# dsPIC33FJ64GS606 register map
Vendor: Microchip; Series: dsPIC33FJ64GS; File version: 1.4.228
Registers are 16-bit, read-write, no defined reset value unless marked. A register's access mark holds for its fields unless they carry their own. Offsets are from the block's base; [hi:lo] are bit positions; {n}, {i} and the like mark numbered series.

## PWM6 — PWM6 peripheral registers
Base 0x000004C0
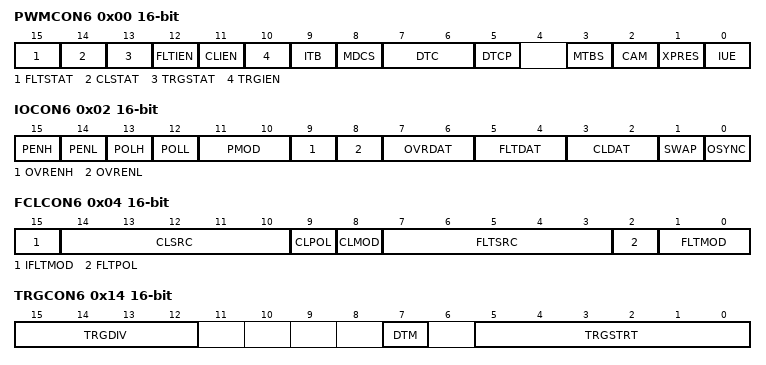
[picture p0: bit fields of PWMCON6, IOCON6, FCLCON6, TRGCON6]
0x00 PWMCON6
  [15] FLTSTAT — PWMCON6 field FLTSTAT
  [14] CLSTAT — PWMCON6 field CLSTAT
  [13] TRGSTAT — PWMCON6 field TRGSTAT
  [12] FLTIEN — PWMCON6 field FLTIEN
  [11] CLIEN — PWMCON6 field CLIEN
  [10] TRGIEN — PWMCON6 field TRGIEN
  [9] ITB — PWMCON6 field ITB
  [8] MDCS — PWMCON6 field MDCS
  [7:6] DTC — PWMCON6 field DTC
  [5] DTCP — PWMCON6 field DTCP
  [3] MTBS — PWMCON6 field MTBS
  [2] CAM — PWMCON6 field CAM
  [1] XPRES — PWMCON6 field XPRES
  [0] IUE — PWMCON6 field IUE
0x02 IOCON6
  [15] PENH — IOCON6 field PENH
  [14] PENL — IOCON6 field PENL
  [13] POLH — IOCON6 field POLH
  [12] POLL — IOCON6 field POLL
  [11:10] PMOD — IOCON6 field PMOD
  [9] OVRENH — IOCON6 field OVRENH
  [8] OVRENL — IOCON6 field OVRENL
  [7:6] OVRDAT — IOCON6 field OVRDAT
  [5:4] FLTDAT — IOCON6 field FLTDAT
  [3:2] CLDAT — IOCON6 field CLDAT
  [1] SWAP — IOCON6 field SWAP
  [0] OSYNC — IOCON6 field OSYNC
0x04 FCLCON6
  [15] IFLTMOD — FCLCON6 field IFLTMOD
  [14:10] CLSRC — FCLCON6 field CLSRC
  [9] CLPOL — FCLCON6 field CLPOL
  [8] CLMOD — FCLCON6 field CLMOD
  [7:3] FLTSRC — FCLCON6 field FLTSRC
  [2] FLTPOL — FCLCON6 field FLTPOL
  [1:0] FLTMOD — FCLCON6 field FLTMOD
0x06 PDC6
  [15:0] PDC6 — PDC6 register value
0x08 PHASE6
  [15:0] PHASE6 — PHASE6 register value
0x0A DTR6
  [13:0] DTR — DTR6 dead-time value
0x0C ALTDTR6
  [13:0] ALTDTR — ALTDTR6 dead-time value
0x0E SDC6
  [15:0] SDC6 — SDC6 register value
0x10 SPHASE6
  [15:0] SPHASE6 — SPHASE6 register value
0x12 TRIG6
  [15:3] TRGCMP — TRIG6 field TRGCMP
0x14 TRGCON6
  [15:12] TRGDIV — TRGCON6 field TRGDIV
  [7] DTM — TRGCON6 field DTM
  [5:0] TRGSTRT — TRGCON6 field TRGSTRT
0x16 STRIG6
  [15:3] STRGCMP — STRIG6 field STRGCMP
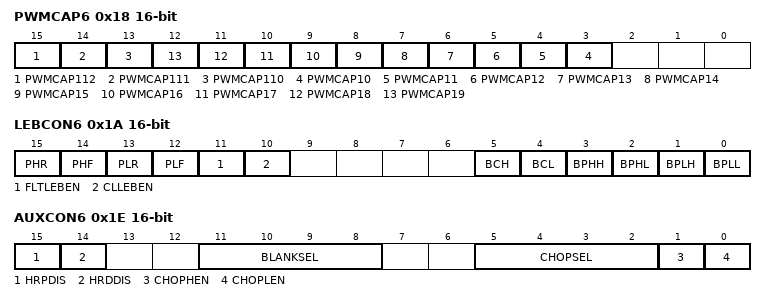
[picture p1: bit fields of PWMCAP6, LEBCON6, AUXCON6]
0x18 PWMCAP6
  [15] PWMCAP112 — PWMCAP6 field PWMCAP112
  [14] PWMCAP111 — PWMCAP6 field PWMCAP111
  [13] PWMCAP110 — PWMCAP6 field PWMCAP110
  [n-7] PWMCAP{n} (n=10..19) — PWMCAP6 field PWMCAP{n}
0x1A LEBCON6
  [15] PHR — LEBCON6 field PHR
  [14] PHF — LEBCON6 field PHF
  [13] PLR — LEBCON6 field PLR
  [12] PLF — LEBCON6 field PLF
  [11] FLTLEBEN — LEBCON6 field FLTLEBEN
  [10] CLLEBEN — LEBCON6 field CLLEBEN
  [5] BCH — LEBCON6 field BCH
  [4] BCL — LEBCON6 field BCL
  [3] BPHH — LEBCON6 field BPHH
  [2] BPHL — LEBCON6 field BPHL
  [1] BPLH — LEBCON6 field BPLH
  [0] BPLL — LEBCON6 field BPLL
0x1C LEBDLY6
  [11:3] LEB — LEBDLY6 field LEB
0x1E AUXCON6
  [15] HRPDIS — AUXCON6 field HRPDIS
  [14] HRDDIS — AUXCON6 field HRDDIS
  [11:8] BLANKSEL — AUXCON6 field BLANKSEL
  [5:2] CHOPSEL — AUXCON6 field CHOPSEL
  [1] CHOPHEN — AUXCON6 field CHOPHEN
  [0] CHOPLEN — AUXCON6 field CHOPLEN

## CMP1 — CMP1 peripheral registers
Base 0x00000540
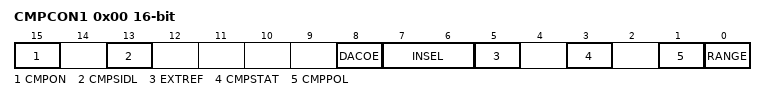
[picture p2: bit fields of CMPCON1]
0x00 CMPCON1
  [15] CMPON — CMPCON1 field CMPON
  [13] CMPSIDL — CMPCON1 field CMPSIDL
  [8] DACOE — CMPCON1 field DACOE
  [7:6] INSEL — CMPCON1 field INSEL
  [5] EXTREF — CMPCON1 field EXTREF
  [3] CMPSTAT — CMPCON1 field CMPSTAT
  [1] CMPPOL — CMPCON1 field CMPPOL
  [0] RANGE — CMPCON1 field RANGE
0x02 CMPDAC1
  [9:0] CMREF — CMPDAC1 field CMREF

## CMP2 — CMP2 peripheral registers
Base 0x00000544
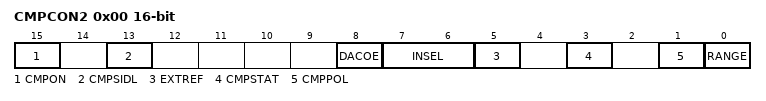
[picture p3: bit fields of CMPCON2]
0x00 CMPCON2
  [15] CMPON — CMPCON2 field CMPON
  [13] CMPSIDL — CMPCON2 field CMPSIDL
  [8] DACOE — CMPCON2 field DACOE
  [7:6] INSEL — CMPCON2 field INSEL
  [5] EXTREF — CMPCON2 field EXTREF
  [3] CMPSTAT — CMPCON2 field CMPSTAT
  [1] CMPPOL — CMPCON2 field CMPPOL
  [0] RANGE — CMPCON2 field RANGE
0x02 CMPDAC2
  [9:0] CMREF — CMPDAC2 field CMREF

## CMP3 — CMP3 peripheral registers
Base 0x00000548
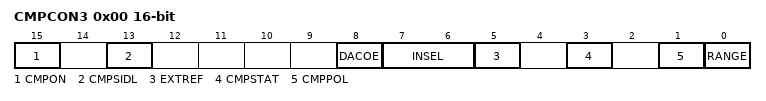
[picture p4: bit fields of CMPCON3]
0x00 CMPCON3
  [15] CMPON — CMPCON3 field CMPON
  [13] CMPSIDL — CMPCON3 field CMPSIDL
  [8] DACOE — CMPCON3 field DACOE
  [7:6] INSEL — CMPCON3 field INSEL
  [5] EXTREF — CMPCON3 field EXTREF
  [3] CMPSTAT — CMPCON3 field CMPSTAT
  [1] CMPPOL — CMPCON3 field CMPPOL
  [0] RANGE — CMPCON3 field RANGE
0x02 CMPDAC3
  [9:0] CMREF — CMPDAC3 field CMREF
